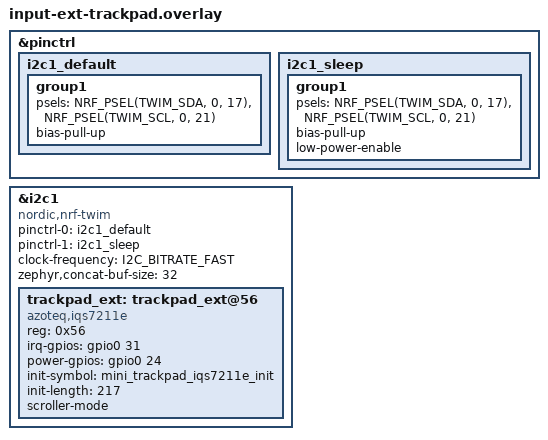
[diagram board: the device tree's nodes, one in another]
/* ★未検証★ 拡張基板の FFC に載せる2個目のポインティングデバイス
 *
 * 純正の拡張 FFC ポート (P0.16/18/19/20) はトラックボール・トラックパッド・
 * ハイレゾダイヤル・4方向スイッチで取り合いになる。BMP Boost の
 * 「追加IOポート」を別の FFC で引き出す小基板を使うと、そちらは別ピンなので
 * 同じ半分に2個目を載せられる。
 *   - BMP Boost LED Extender (せきごんさん / キーフリ2026 配布品)
 *   - ngsyst/bmp_boost_extender_mini  (17.8 x 14.5mm、JLCPCB へ発注するタイプ)
 * どちらも同じ4本を出す。
 *
 * ── いまの構成 ───────────────────────────────────────────────
 *   左 純正ポート (i2c0)      ハイレゾダイヤル   → input-hires-dial
 *   左 エクステンダー (i2c1)  ミニトラックパッド → このスニペット
 *   右 純正ポート             トラックボール     → input-trackball
 * 左は peripheral なので、このパッドの入力は zmk,input-split で central へ
 * 転送する → input-ext-split (送り側) / input-ext-split-listener (受け側)。
 * central 側に直付けするなら代わりに input-ext-trackpad-listener を使う。
 *
 * ── ピン ─────────────────────────────────────────────────────
 *   SDA   P0.17        SCL   P0.21
 *   RDY   P0.31        電源  P0.24
 *   I2C アドレス 0x56 (純正ポートのパッドと同じだが別バス)
 *
 * ★P0.24 は LED Extender では3色LEDの共通アノードも兼ねている。
 *  ここの power-gpios が High にすることで、LED 側にも電源が回る。
 *  (LED を光らせるには別途 snippets/led-plus が要る。いまは使っていない。)
 *
 * 同じ2本 (P0.17 / P0.21) に spi1 を張ればトラックボールを、
 * GPIO のまま使えば EC11 ロータリーエンコーダを載せられる。
 * その場合はこの overlay を複製して中身を差し替える。
 *
 * ── 未検証事項 ──
 *  1. bmp_boost のボード定義が i2c1 を他で使っていないか
 *  2. nRF52840 では TWIM1 と SPIM1 が同じペリフェラルなので併用不可。
 *     ext-trackball 版を作るときは同時指定しないこと
 *  3. 実物を繋いでいないので、向き (v-invert / h-invert) は未調整
 *  4. 拡張基板と純正モジュールで FFC のピン「順」が合うかは現物合わせ
 */

#include <zephyr/dt-bindings/gpio/gpio.h>
#include <zephyr/dt-bindings/i2c/i2c.h>
#include <zephyr/dt-bindings/gpio/nordic-nrf-gpio.h>

&pinctrl {
    i2c1_default: i2c1_default {
        group1 {
            psels = <NRF_PSEL(TWIM_SDA, 0, 17)>,
                    <NRF_PSEL(TWIM_SCL, 0, 21)>;
            bias-pull-up;
        };
    };

    i2c1_sleep: i2c1_sleep {
        group1 {
            psels = <NRF_PSEL(TWIM_SDA, 0, 17)>,
                    <NRF_PSEL(TWIM_SCL, 0, 21)>;
            bias-pull-up;
            low-power-enable;
        };
    };
};

&i2c1 {
    status = "okay";
    compatible = "nordic,nrf-twim";
    pinctrl-0 = <&i2c1_default>;
    pinctrl-1 = <&i2c1_sleep>;
    pinctrl-names = "default", "sleep";
    clock-frequency = <I2C_BITRATE_FAST>;
    zephyr,concat-buf-size = <32>;

    /* ノード名・ラベルを pointing_device にしないこと。
     * 純正ポート側のトラックボール/パッドがそのラベルを使っている。 */
    trackpad_ext: trackpad_ext@56 {
        status = "okay";
        compatible = "azoteq,iqs7211e";
        reg = <0x56>;
        irq-gpios = <&gpio0 31 GPIO_PULL_UP>;
        power-gpios = <&gpio0 24 (GPIO_ACTIVE_HIGH | NRF_GPIO_DRIVE_H1)>;

        /* 純正の「ミニトラックパッド」を挿す前提。初期化テーブルは
         * リポジトリ内の src/mini_trackpad_init_reg.c にある実体を指す
         * (input-trackpad{,-mini} と同じもの)。
         * 30/40mm の円形モジュールを挿すならこの2行を削る = ドライバ既定。 */
        init-symbol = "mini_trackpad_iqs7211e_init";
        init-length = <217>;

        /* 指の移動を X/Y ではなく INPUT_REL_WHEEL として報告する。
         * ダイヤルで縦スクロール / パッドで面スクロールという分担ならこれ。
         * カーソルとして使うならこの行を削り、受け側のリスナーに
         * zip_xy_transform などを足すこと。 */
        scroller-mode;
    };
};
